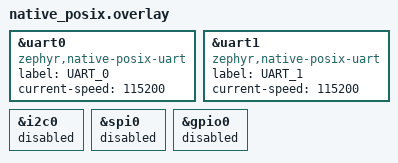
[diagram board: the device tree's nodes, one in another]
&uart0 {
    status = "okay";
    compatible = "zephyr,native-posix-uart";
    label = "UART_0";
    current-speed = <115200>;
};
&uart1 {
    status = "okay";
    compatible = "zephyr,native-posix-uart";
    label = "UART_1";
    current-speed = <115200>;
};

&i2c0 {
    status = "disabled";
};

&spi0 {
    status = "disabled";
};

&gpio0 {
    status = "disabled";
};
